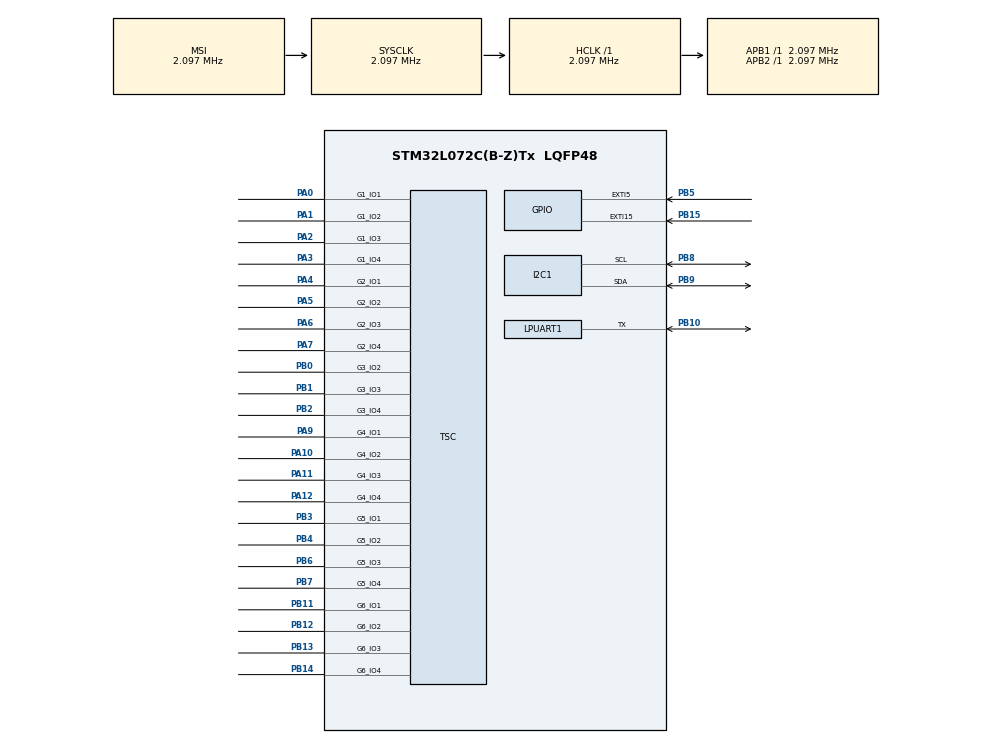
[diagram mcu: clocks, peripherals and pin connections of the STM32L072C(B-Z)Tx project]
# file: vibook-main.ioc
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I2C1.Timing=0x00000608
LPUART1.BaudRate=9600
LPUART1.WordLength=UART_WORDLENGTH_8B
Mcu.Family=STM32L0
Mcu.Name=STM32L072C(B-Z)Tx
Mcu.Package=LQFP48
NVIC.EXTI4_15_IRQn=true\:0\:0\:false\:false\:true\:true\:true\:true
NVIC.TSC_IRQn=true\:0\:0\:false\:false\:true\:true\:true\:true
PA0.Mode=G1_IO1-Sampling
PA0.Signal=TSC_G1_IO1
PA1.Mode=G1_IO2-Channel
PA1.Signal=TSC_G1_IO2
PA10.Mode=G4_IO2-Channel
PA10.Signal=TSC_G4_IO2
PA11.Mode=G4_IO3-Channel
PA11.Signal=TSC_G4_IO3
PA12.Mode=G4_IO4-Channel
PA12.Signal=TSC_G4_IO4
PA13.Mode=Serial_Wire
PA13.Signal=SYS_SWDIO
PA14.Mode=Serial_Wire
PA14.Signal=SYS_SWCLK
PA2.Mode=G1_IO3-Channel
PA2.Signal=TSC_G1_IO3
PA3.Mode=G1_IO4-Channel
PA3.Signal=TSC_G1_IO4
PA4.Mode=G2_IO1-Sampling
PA4.Signal=TSC_G2_IO1
PA5.Mode=G2_IO2-Channel
PA5.Signal=TSC_G2_IO2
PA6.Mode=G2_IO3-Channel
PA6.Signal=TSC_G2_IO3
PA7.Mode=G2_IO4-Channel
PA7.Signal=TSC_G2_IO4
PA9.Mode=G4_IO1-Sampling
PA9.Signal=TSC_G4_IO1
PB0.Mode=G3_IO2-Sampling
PB0.Signal=TSC_G3_IO2
PB1.Mode=G3_IO3-Channel
PB1.Signal=TSC_G3_IO3
PB10.Mode=Half_duplex(single_wire_mode)
PB10.Signal=LPUART1_TX
PB11.Mode=G6_IO1-Sampling
PB11.Signal=TSC_G6_IO1
PB12.Mode=G6_IO2-Channel
PB12.Signal=TSC_G6_IO2
PB13.Mode=G6_IO3-Channel
PB13.Signal=TSC_G6_IO3
PB14.Mode=G6_IO4-Channel
PB14.Signal=TSC_G6_IO4
PB15.GPIO_ModeDefaultEXTI=GPIO_MODE_IT_FALLING
PB15.Signal=GPXTI15
PB2.Mode=G3_IO4-Channel
PB2.Signal=TSC_G3_IO4
PB3.Mode=G5_IO1-Channel
PB3.Signal=TSC_G5_IO1
PB4.Mode=G5_IO2-Channel
PB4.Signal=TSC_G5_IO2
PB5.GPIO_ModeDefaultEXTI=GPIO_MODE_IT_FALLING
PB5.Signal=GPXTI5
PB6.Mode=G5_IO3-Sampling
PB6.Signal=TSC_G5_IO3
PB7.Mode=G5_IO4-Channel
PB7.Signal=TSC_G5_IO4
PB8.Mode=I2C
PB8.Signal=I2C1_SCL
PB9.Mode=I2C
PB9.Signal=I2C1_SDA
ProjectManager.HeapSize=0x200
ProjectManager.StackSize=0x400
ProjectManager.TargetToolchain=STM32CubeIDE
RCC.AHBFreq_Value=2097000
RCC.APB1Freq_Value=2097000
RCC.APB1TimFreq_Value=2097000
RCC.APB2Freq_Value=2097000
RCC.APB2TimFreq_Value=2097000
RCC.HSE_VALUE=8000000
RCC.HSI16_VALUE=16000000
RCC.HSI48_VALUE=48000000
RCC.HSI_VALUE=16000000
RCC.LSE_VALUE=32768
RCC.MSI_VALUE=2097000
RCC.SYSCLKFreq_VALUE=2097000
RCC.VCOOutputFreq_Value=48000000
TSC.ChannelIOs-G1_IO2=TSC_GROUP1_IO2
TSC.ChannelIOs-G1_IO2-Channel=TSC_GROUP1_IO2
TSC.ChannelIOs-G1_IO3=TSC_GROUP1_IO3
TSC.ChannelIOs-G1_IO3-Channel=TSC_GROUP1_IO3
TSC.ChannelIOs-G1_IO4=TSC_GROUP1_IO4
TSC.ChannelIOs-G1_IO4-Channel=TSC_GROUP1_IO4
TSC.ChannelIOs-G2_IO2=TSC_GROUP2_IO2
TSC.ChannelIOs-G2_IO2-Channel=TSC_GROUP2_IO2
TSC.ChannelIOs-G2_IO3=TSC_GROUP2_IO3
TSC.ChannelIOs-G2_IO3-Channel=TSC_GROUP2_IO3
TSC.ChannelIOs-G2_IO4=TSC_GROUP2_IO4
TSC.ChannelIOs-G2_IO4-Channel=TSC_GROUP2_IO4
TSC.ChannelIOs-G3_IO3=TSC_GROUP3_IO3
TSC.ChannelIOs-G3_IO3-Channel=TSC_GROUP3_IO3
TSC.ChannelIOs-G3_IO4=TSC_GROUP3_IO4
TSC.ChannelIOs-G3_IO4-Channel=TSC_GROUP3_IO4
TSC.ChannelIOs-G4_IO2=TSC_GROUP4_IO2
TSC.ChannelIOs-G4_IO2-Channel=TSC_GROUP4_IO2
TSC.ChannelIOs-G4_IO3=TSC_GROUP4_IO3
TSC.ChannelIOs-G4_IO3-Channel=TSC_GROUP4_IO3
TSC.ChannelIOs-G4_IO4=TSC_GROUP4_IO4
TSC.ChannelIOs-G4_IO4-Channel=TSC_GROUP4_IO4
TSC.ChannelIOs-G5_IO1=TSC_GROUP5_IO1
TSC.ChannelIOs-G5_IO1-Channel=TSC_GROUP5_IO1
TSC.ChannelIOs-G5_IO2=TSC_GROUP5_IO2
TSC.ChannelIOs-G5_IO2-Channel=TSC_GROUP5_IO2
TSC.ChannelIOs-G5_IO4=TSC_GROUP5_IO4
TSC.ChannelIOs-G5_IO4-Channel=TSC_GROUP5_IO4
TSC.ChannelIOs-G6_IO2=TSC_GROUP6_IO2
TSC.ChannelIOs-G6_IO2-Channel=TSC_GROUP6_IO2
TSC.ChannelIOs-G6_IO3=TSC_GROUP6_IO3
TSC.ChannelIOs-G6_IO3-Channel=TSC_GROUP6_IO3
TSC.ChannelIOs-G6_IO4=TSC_GROUP6_IO4
TSC.ChannelIOs-G6_IO4-Channel=TSC_GROUP6_IO4
TSC.SamplingIOs-G1_IO1=TSC_GROUP1_IO1
TSC.SamplingIOs-G1_IO1-Sampling=TSC_GROUP1_IO1
TSC.SamplingIOs-G2_IO1=TSC_GROUP2_IO1
TSC.SamplingIOs-G2_IO1-Sampling=TSC_GROUP2_IO1
TSC.SamplingIOs-G3_IO2=TSC_GROUP3_IO2
TSC.SamplingIOs-G3_IO2-Sampling=TSC_GROUP3_IO2
TSC.SamplingIOs-G4_IO1=TSC_GROUP4_IO1
TSC.SamplingIOs-G4_IO1-Sampling=TSC_GROUP4_IO1
TSC.SamplingIOs-G5_IO3=TSC_GROUP5_IO3
TSC.SamplingIOs-G5_IO3-Sampling=TSC_GROUP5_IO3
TSC.SamplingIOs-G6_IO1=TSC_GROUP6_IO1
TSC.SamplingIOs-G6_IO1-Sampling=TSC_GROUP6_IO1
board=custom

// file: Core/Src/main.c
/* USER CODE BEGIN Header */
/**
  ******************************************************************************
  * @file           : main.c
  * @brief          : Main program body
  ******************************************************************************
  * @attention
  *
  * Copyright (c) 2026 STMicroelectronics.
  * All rights reserved.
  *
  * This software is licensed under terms that can be found in the LICENSE file
  * in the root directory of this software component.
  * If no LICENSE file comes with this software, it is provided AS-IS.
  *
  ******************************************************************************
  */
/* USER CODE END Header */
#include "main.h"

I2C_HandleTypeDef hi2c1;

UART_HandleTypeDef hlpuart1;

TSC_HandleTypeDef htsc;

void SystemClock_Config(void);
static void MX_GPIO_Init(void);
static void MX_I2C1_Init(void);
static void MX_LPUART1_UART_Init(void);
static void MX_TSC_Init(void);

int main(void)
{

  /* MCU Configuration--------------------------------------------------------*/

  /* Reset of all peripherals, Initializes the Flash interface and the Systick. */
  HAL_Init();

  /* Configure the system clock */
  SystemClock_Config();

  /* Initialize all configured peripherals */
  MX_GPIO_Init();
  MX_I2C1_Init();
  MX_LPUART1_UART_Init();
  MX_TSC_Init();
  /* USER CODE BEGIN 2 */

  uint16_t tscs[24];

  /* USER CODE END 2 */

  /* Infinite loop */
  while (1)
  {

  }
}

void SystemClock_Config(void)
{
  RCC_OscInitTypeDef RCC_OscInitStruct = {0};
  RCC_ClkInitTypeDef RCC_ClkInitStruct = {0};
  RCC_PeriphCLKInitTypeDef PeriphClkInit = {0};

  /** Configure the main internal regulator output voltage
  */
  __HAL_PWR_VOLTAGESCALING_CONFIG(PWR_REGULATOR_VOLTAGE_SCALE1);

  /** Initializes the RCC Oscillators according to the specified parameters
  * in the RCC_OscInitTypeDef structure.
  */
  RCC_OscInitStruct.OscillatorType = RCC_OSCILLATORTYPE_MSI;
  RCC_OscInitStruct.MSIState = RCC_MSI_ON;
  RCC_OscInitStruct.MSICalibrationValue = 0;
  RCC_OscInitStruct.MSIClockRange = RCC_MSIRANGE_5;
  RCC_OscInitStruct.PLL.PLLState = RCC_PLL_NONE;
  if (HAL_RCC_OscConfig(&RCC_OscInitStruct) != HAL_OK)
  {
    Error_Handler();
  }

  /** Initializes the CPU, AHB and APB buses clocks
  */
  RCC_ClkInitStruct.ClockType = RCC_CLOCKTYPE_HCLK|RCC_CLOCKTYPE_SYSCLK
                              |RCC_CLOCKTYPE_PCLK1|RCC_CLOCKTYPE_PCLK2;
  RCC_ClkInitStruct.SYSCLKSource = RCC_SYSCLKSOURCE_MSI;
  RCC_ClkInitStruct.AHBCLKDivider = RCC_SYSCLK_DIV1;
  RCC_ClkInitStruct.APB1CLKDivider = RCC_HCLK_DIV1;
  RCC_ClkInitStruct.APB2CLKDivider = RCC_HCLK_DIV1;

  if (HAL_RCC_ClockConfig(&RCC_ClkInitStruct, FLASH_LATENCY_0) != HAL_OK)
  {
    Error_Handler();
  }
  PeriphClkInit.PeriphClockSelection = RCC_PERIPHCLK_LPUART1|RCC_PERIPHCLK_I2C1;
  PeriphClkInit.Lpuart1ClockSelection = RCC_LPUART1CLKSOURCE_PCLK1;
  PeriphClkInit.I2c1ClockSelection = RCC_I2C1CLKSOURCE_PCLK1;
  if (HAL_RCCEx_PeriphCLKConfig(&PeriphClkInit) != HAL_OK)
  {
    Error_Handler();
  }
}

static void MX_I2C1_Init(void)
{

  hi2c1.Instance = I2C1;
  hi2c1.Init.Timing = 0x00000608;
  hi2c1.Init.OwnAddress1 = 0;
  hi2c1.Init.AddressingMode = I2C_ADDRESSINGMODE_7BIT;
  hi2c1.Init.DualAddressMode = I2C_DUALADDRESS_DISABLE;
  hi2c1.Init.OwnAddress2 = 0;
  hi2c1.Init.OwnAddress2Masks = I2C_OA2_NOMASK;
  hi2c1.Init.GeneralCallMode = I2C_GENERALCALL_DISABLE;
  hi2c1.Init.NoStretchMode = I2C_NOSTRETCH_DISABLE;
  if (HAL_I2C_Init(&hi2c1) != HAL_OK)
  {
    Error_Handler();
  }

  /** Configure Analogue filter
  */
  if (HAL_I2CEx_ConfigAnalogFilter(&hi2c1, I2C_ANALOGFILTER_ENABLE) != HAL_OK)
  {
    Error_Handler();
  }

  /** Configure Digital filter
  */
  if (HAL_I2CEx_ConfigDigitalFilter(&hi2c1, 0) != HAL_OK)
  {
    Error_Handler();
  }

}

static void MX_LPUART1_UART_Init(void)
{

  hlpuart1.Instance = LPUART1;
  hlpuart1.Init.BaudRate = 9600;
  hlpuart1.Init.WordLength = UART_WORDLENGTH_8B;
  hlpuart1.Init.StopBits = UART_STOPBITS_1;
  hlpuart1.Init.Parity = UART_PARITY_NONE;
  hlpuart1.Init.Mode = UART_MODE_TX_RX;
  hlpuart1.Init.HwFlowCtl = UART_HWCONTROL_NONE;
  hlpuart1.Init.OneBitSampling = UART_ONE_BIT_SAMPLE_DISABLE;
  hlpuart1.AdvancedInit.AdvFeatureInit = UART_ADVFEATURE_NO_INIT;
  if (HAL_HalfDuplex_Init(&hlpuart1) != HAL_OK)
  {
    Error_Handler();
  }

}

static void MX_TSC_Init(void)
{

  /** Configure the TSC peripheral
  */
  htsc.Instance = TSC;
  htsc.Init.CTPulseHighLength = TSC_CTPH_2CYCLES;
  htsc.Init.CTPulseLowLength = TSC_CTPL_2CYCLES;
  htsc.Init.SpreadSpectrum = DISABLE;
  htsc.Init.SpreadSpectrumDeviation = 1;
  htsc.Init.SpreadSpectrumPrescaler = TSC_SS_PRESC_DIV1;
  htsc.Init.PulseGeneratorPrescaler = TSC_PG_PRESC_DIV4;
  htsc.Init.MaxCountValue = TSC_MCV_8191;
  htsc.Init.IODefaultMode = TSC_IODEF_OUT_PP_LOW;
  htsc.Init.SynchroPinPolarity = TSC_SYNC_POLARITY_FALLING;
  htsc.Init.AcquisitionMode = TSC_ACQ_MODE_NORMAL;
  htsc.Init.MaxCountInterrupt = DISABLE;
  htsc.Init.ChannelIOs = TSC_GROUP1_IO2|TSC_GROUP1_IO3|TSC_GROUP1_IO4|TSC_GROUP2_IO2
                    |TSC_GROUP2_IO3|TSC_GROUP2_IO4|TSC_GROUP3_IO3|TSC_GROUP3_IO4
                    |TSC_GROUP4_IO2|TSC_GROUP4_IO3|TSC_GROUP4_IO4|TSC_GROUP5_IO1
                    |TSC_GROUP5_IO2|TSC_GROUP5_IO4|TSC_GROUP6_IO2|TSC_GROUP6_IO3
                    |TSC_GROUP6_IO4;
  htsc.Init.ShieldIOs = 0;
  htsc.Init.SamplingIOs = TSC_GROUP1_IO1|TSC_GROUP2_IO1|TSC_GROUP3_IO2|TSC_GROUP4_IO1
                    |TSC_GROUP5_IO3|TSC_GROUP6_IO1;
  if (HAL_TSC_Init(&htsc) != HAL_OK)
  {
    Error_Handler();
  }

}

static void MX_GPIO_Init(void)
{
  GPIO_InitTypeDef GPIO_InitStruct = {0};

  /* GPIO Ports Clock Enable */
  __HAL_RCC_GPIOA_CLK_ENABLE();
  __HAL_RCC_GPIOB_CLK_ENABLE();

  /*Configure GPIO pins : PB15 PB5 */
  GPIO_InitStruct.Pin = GPIO_PIN_15|GPIO_PIN_5;
  GPIO_InitStruct.Mode = GPIO_MODE_IT_FALLING;
  GPIO_InitStruct.Pull = GPIO_NOPULL;
  HAL_GPIO_Init(GPIOB, &GPIO_InitStruct);

  /* EXTI interrupt init*/
  HAL_NVIC_SetPriority(EXTI4_15_IRQn, 0, 0);
  HAL_NVIC_EnableIRQ(EXTI4_15_IRQn);

}

void Error_Handler(void)
{
  __disable_irq();
  while (1)
  {
  }
}
